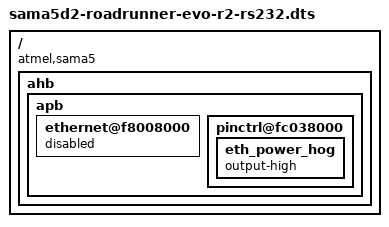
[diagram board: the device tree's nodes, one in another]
/dts-v1/;
/plugin/;

/ {
    fragment@111111_rs232 {
        target-path = "/";
        __overlay__ {
            compatible = "atmel,sama5", "atmel,sama5d2", "atmel,sama5d2-evo-r2-rs232";
            ahb {
                apb {
                    ethernet@f8008000 {
                        status = "disabled";
                    };

                    pinctrl@fc038000 {
                        eth_power_hog {
                            output-high;
                        };
                    };
                };
            };
        };
    };
};
